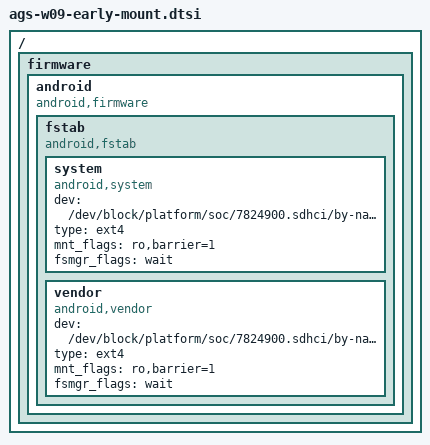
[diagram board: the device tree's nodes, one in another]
/* Android 8 first-stage mounts for the original AGS-W09 GPT layout. */
/ {
    firmware {
        android {
            compatible = "android,firmware";
            fstab {
                compatible = "android,fstab";
                system {
                    compatible = "android,system";
                    dev = "/dev/block/platform/soc/7824900.sdhci/by-name/system";
                    type = "ext4";
                    mnt_flags = "ro,barrier=1";
                    fsmgr_flags = "wait";
                };
                vendor {
                    compatible = "android,vendor";
                    dev = "/dev/block/platform/soc/7824900.sdhci/by-name/vendor";
                    type = "ext4";
                    mnt_flags = "ro,barrier=1";
                    fsmgr_flags = "wait";
                };
            };
        };
    };
};
